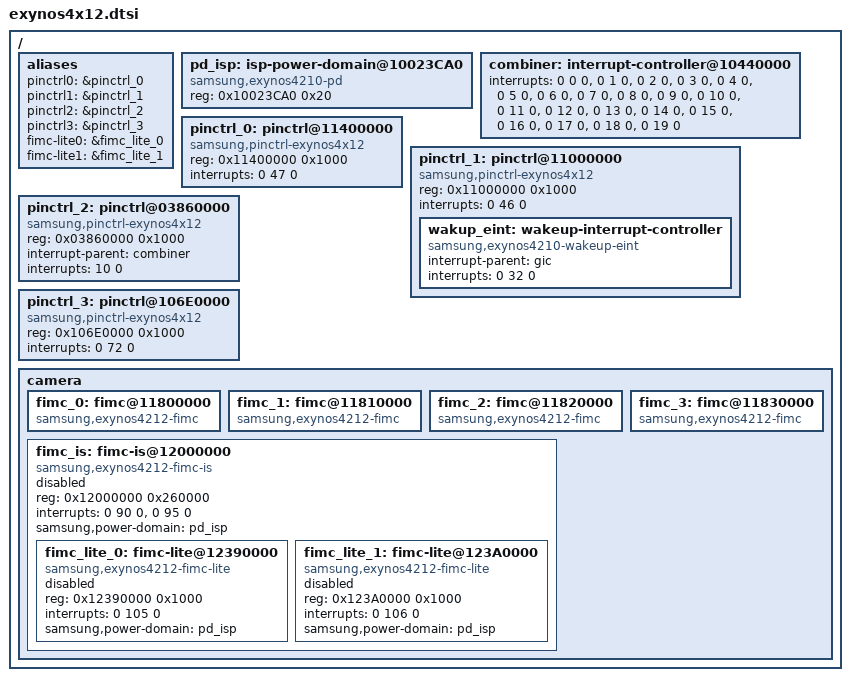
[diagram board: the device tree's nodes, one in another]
/*
 * Samsung's Exynos4x12 SoCs device tree source
 *
 * Copyright (c) 2012 Samsung Electronics Co., Ltd.
 *		http://www.samsung.com
 *
 * Samsung's Exynos4x12 SoCs device nodes are listed in this file. Exynos4x12
 * based board files can include this file and provide values for board specfic
 * bindings.
 *
 * Note: This file does not include device nodes for all the controllers in
 * Exynos4x12 SoC. As device tree coverage for Exynos4x12 increases, additional
 * nodes can be added to this file.
 *
 * This program is free software; you can redistribute it and/or modify
 * it under the terms of the GNU General Public License version 2 as
 * published by the Free Software Foundation.
*/

/include/ "exynos4.dtsi"
/include/ "exynos4x12-pinctrl.dtsi"

/ {
	aliases {
		pinctrl0 = &pinctrl_0;
		pinctrl1 = &pinctrl_1;
		pinctrl2 = &pinctrl_2;
		pinctrl3 = &pinctrl_3;
		fimc-lite0 = &fimc_lite_0;
		fimc-lite1 = &fimc_lite_1;
	};

	pd_isp: isp-power-domain@10023CA0 {
		compatible = "samsung,exynos4210-pd";
		reg = <0x10023CA0 0x20>;
	};

	combiner:interrupt-controller@10440000 {
		interrupts = <0 0 0>, <0 1 0>, <0 2 0>, <0 3 0>,
			     <0 4 0>, <0 5 0>, <0 6 0>, <0 7 0>,
			     <0 8 0>, <0 9 0>, <0 10 0>, <0 11 0>,
			     <0 12 0>, <0 13 0>, <0 14 0>, <0 15 0>,
			     <0 16 0>, <0 17 0>, <0 18 0>, <0 19 0>;
	};

	pinctrl_0: pinctrl@11400000 {
		compatible = "samsung,pinctrl-exynos4x12";
		reg = <0x11400000 0x1000>;
		interrupts = <0 47 0>;
	};

	pinctrl_1: pinctrl@11000000 {
		compatible = "samsung,pinctrl-exynos4x12";
		reg = <0x11000000 0x1000>;
		interrupts = <0 46 0>;

		wakup_eint: wakeup-interrupt-controller {
			compatible = "samsung,exynos4210-wakeup-eint";
			interrupt-parent = <&gic>;
			interrupts = <0 32 0>;
		};
	};

	pinctrl_2: pinctrl@03860000 {
		compatible = "samsung,pinctrl-exynos4x12";
		reg = <0x03860000 0x1000>;
		interrupt-parent = <&combiner>;
		interrupts = <10 0>;
	};

	pinctrl_3: pinctrl@106E0000 {
		compatible = "samsung,pinctrl-exynos4x12";
		reg = <0x106E0000 0x1000>;
		interrupts = <0 72 0>;
	};

	camera {
		fimc_0: fimc@11800000 {
			compatible = "samsung,exynos4212-fimc";
		};

		fimc_1: fimc@11810000 {
			compatible = "samsung,exynos4212-fimc";
		};

		fimc_2: fimc@11820000 {
			compatible = "samsung,exynos4212-fimc";
		};

		fimc_3: fimc@11830000 {
			compatible = "samsung,exynos4212-fimc";
		};

		fimc_is: fimc-is@12000000 {
			compatible = "samsung,exynos4212-fimc-is", "simple-bus";
			reg = <0x12000000 0x260000>;
			interrupts = <0 90 0>, <0 95 0>;
			samsung,power-domain = <&pd_isp>;
			status = "disabled";
			#address-cells = <1>;
			#size-cells = <1>;
			ranges;

			fimc_lite_0: fimc-lite@12390000 {
				compatible = "samsung,exynos4212-fimc-lite";
				reg = <0x12390000 0x1000>;
				interrupts = <0 105 0>;
				samsung,power-domain = <&pd_isp>;
				status = "disabled";
			};

			fimc_lite_1: fimc-lite@123A0000 {
				compatible = "samsung,exynos4212-fimc-lite";
				reg = <0x123A0000 0x1000>;
				interrupts = <0 106 0>;
				samsung,power-domain = <&pd_isp>;
				status = "disabled";
			};
		};
	};
};
